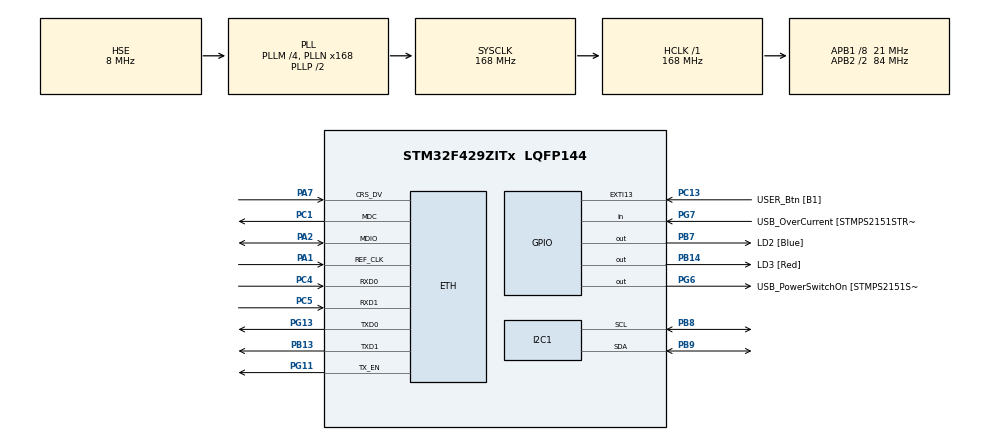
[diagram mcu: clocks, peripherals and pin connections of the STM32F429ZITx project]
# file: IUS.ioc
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ETH.MACAddr=00\:80\:E1\:E2\:13\:77
ETH.MediaInterface=ETH_MEDIA_INTERFACE_RMII
ETH.PhyAddress=0
LWIP.API_MSG_DEBUG=LWIP_DBG_ON
LWIP.AUTOIP_DEBUG=LWIP_DBG_ON
LWIP.DHCP_DEBUG=LWIP_DBG_ON
LWIP.DNS_DEBUG=LWIP_DBG_ON
LWIP.ICMP_DEBUG=LWIP_DBG_ON
LWIP.IGMP_DEBUG=LWIP_DBG_ON
LWIP.INET_DEBUG=LWIP_DBG_ON
LWIP.IP_DEBUG=LWIP_DBG_ON
LWIP.LWIP_DBG_TYPES_ON=LWIP_DBG_OFF
LWIP.LWIP_DNS=1
LWIP.LWIP_NETIF_LINK_CALLBACK=1
LWIP.LWIP_NETIF_LOOPBACK=1
LWIP.LWIP_NETIF_STATUS_CALLBACK=1
LWIP.LWIP_SNTP=1
LWIP.LWIP_STATS=1
LWIP.MEMP_NUM_PBUF=32
LWIP.MEMP_NUM_SYS_TIMEOUT=10
LWIP.MEMP_NUM_TCP_PCB_LISTEN=4
LWIP.MEMP_NUM_TCP_SEG=32
LWIP.MEM_SIZE=65536
LWIP.NETIF_DEBUG=LWIP_DBG_OFF
LWIP.PBUF_DEBUG=LWIP_DBG_OFF
LWIP.SOCKETS_DEBUG=LWIP_DBG_ON
LWIP.TCPIP_DEBUG=LWIP_DBG_OFF
LWIP.TCP_DEBUG=LWIP_DBG_OFF
LWIP.TCP_INPUT_DEBUG=LWIP_DBG_OFF
LWIP.TCP_OUTPUT_DEBUG=LWIP_DBG_OFF
LWIP.UDP_DEBUG=LWIP_DBG_OFF
LWIP.Version=v2.0.3_Cube
Mcu.Family=STM32F4
Mcu.Name=STM32F429ZITx
Mcu.Package=LQFP144
NVIC.PriorityGroup=NVIC_PRIORITYGROUP_4
NVIC.TIM2_IRQn=true\:0\:0\:false\:false\:true\:true
PA1.Mode=RMII
PA1.Signal=ETH_REF_CLK
PA13.GPIO_Label=TMS
PA13.Signal=SYS_JTMS-SWDIO
PA14.GPIO_Label=TCK
PA14.Signal=SYS_JTCK-SWCLK
PA2.Mode=RMII
PA2.Signal=ETH_MDIO
PA7.Mode=RMII
PA7.Signal=ETH_CRS_DV
PB13.Mode=RMII
PB13.Signal=ETH_TXD1
PB14.GPIO_Label=LD3 [Red]
PB14.Signal=GPIO_Output
PB7.GPIO_Label=LD2 [Blue]
PB7.Signal=GPIO_Output
PB8.Mode=I2C
PB8.Signal=I2C1_SCL
PB9.Mode=I2C
PB9.Signal=I2C1_SDA
PC1.Mode=RMII
PC1.Signal=ETH_MDC
PC13.GPIO_Label=USER_Btn [B1]
PC13.Signal=GPXTI13
PC14/OSC32_IN.Mode=LSE-External-Oscillator
PC14/OSC32_IN.Signal=RCC_OSC32_IN
PC15/OSC32_OUT.Mode=LSE-External-Oscillator
PC15/OSC32_OUT.Signal=RCC_OSC32_OUT
PC4.Mode=RMII
PC4.Signal=ETH_RXD0
PC5.Mode=RMII
PC5.Signal=ETH_RXD1
PG11.Mode=RMII
PG11.Signal=ETH_TX_EN
PG13.Mode=RMII
PG13.Signal=ETH_TXD0
PG6.GPIO_Label=USB_PowerSwitchOn [STMPS2151STR_EN]
PG6.Signal=GPIO_Output
PG7.GPIO_Label=USB_OverCurrent [STMPS2151STR_FAULT]
PG7.Signal=GPIO_Input
PH0/OSC_IN.GPIO_Label=MCO [STM32F103CBT6_PA8]
PH0/OSC_IN.Mode=HSE-External-Clock-Source
PH0/OSC_IN.Signal=RCC_OSC_IN
PH1/OSC_OUT.Mode=HSE-External-Clock-Source
PH1/OSC_OUT.Signal=RCC_OSC_OUT
ProjectManager.HeapSize=0x200
ProjectManager.StackSize=0x400
ProjectManager.TargetToolchain=EWARM V8
RCC.48MHZClocksFreq_Value=48000000
RCC.AHBFreq_Value=168000000
RCC.APB1CLKDivider=RCC_HCLK_DIV8
RCC.APB1Freq_Value=21000000
RCC.APB1TimFreq_Value=42000000
RCC.APB2CLKDivider=RCC_HCLK_DIV2
RCC.APB2Freq_Value=84000000
RCC.APB2TimFreq_Value=168000000
RCC.CortexFreq_Value=168000000
RCC.HCLKFreq_Value=168000000
RCC.HSE_VALUE=8000000
RCC.HSI_VALUE=16000000
RCC.PLLM=4
RCC.PLLMUL=RCC_PLL_MUL9
RCC.PLLN=168
RCC.PLLQ=7
RCC.PLLSourceVirtual=RCC_PLLSOURCE_HSE
RCC.PRESCALERUSB=RCC_USBCLKSOURCE_PLL_DIV1_5
RCC.SYSCLKFreq_VALUE=168000000
RCC.SYSCLKSource=RCC_SYSCLKSOURCE_PLLCLK
RCC.SYSCLKSourceVirtual=RCC_SYSCLKSOURCE_PLLCLK
RCC.USBFreq_Value=48000000
RCC.VCOOutputFreq_Value=336000000
TIM2.Period=300000
TIM2.Prescaler=41999
VP_LWIP_VS_Enabled.Mode=Enabled
VP_TIM2_VS_ClockSourceINT.Mode=Internal
board=NUCLEO-F429ZI

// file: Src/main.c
/**
  ******************************************************************************
  * @file           : main.c
  * @brief          : Main program body
  ******************************************************************************
  * This notice applies to any and all portions of this file
  * that are not between comment pairs USER CODE BEGIN and
  * USER CODE END. Other portions of this file, whether
  * inserted by the user or by software development tools
  * are owned by their respective copyright owners.
  *
  * Copyright (c) 2018 STMicroelectronics International N.V.
  * All rights reserved.
  *
  * Redistribution and use in source and binary forms, with or without
  * modification, are permitted, provided that the following conditions are met:
  *
  * 1. Redistribution of source code must retain the above copyright notice,
  *    this list of conditions and the following disclaimer.
  * 2. Redistributions in binary form must reproduce the above copyright notice,
  *    this list of conditions and the following disclaimer in the documentation
  *    and/or other materials provided with the distribution.
  * 3. Neither the name of STMicroelectronics nor the names of other
  *    contributors to this software may be used to endorse or promote products
  *    derived from this software without specific written permission.
  * 4. This software, including modifications and/or derivative works of this
  *    software, must execute solely and exclusively on microcontroller or
  *    microprocessor devices manufactured by or for STMicroelectronics.
  * 5. Redistribution and use of this software other than as permitted under
  *    this license is void and will automatically terminate your rights under
  *    this license.
  *
  * THIS SOFTWARE IS PROVIDED BY STMICROELECTRONICS AND CONTRIBUTORS "AS IS"
  * AND ANY EXPRESS, IMPLIED OR STATUTORY WARRANTIES, INCLUDING, BUT NOT
  * LIMITED TO, THE IMPLIED WARRANTIES OF MERCHANTABILITY, FITNESS FOR A
  * PARTICULAR PURPOSE AND NON-INFRINGEMENT OF THIRD PARTY INTELLECTUAL PROPERTY
  * RIGHTS ARE DISCLAIMED TO THE FULLEST EXTENT PERMITTED BY LAW. IN NO EVENT
  * SHALL STMICROELECTRONICS OR CONTRIBUTORS BE LIABLE FOR ANY DIRECT, INDIRECT,
  * INCIDENTAL, SPECIAL, EXEMPLARY, OR CONSEQUENTIAL DAMAGES (INCLUDING, BUT NOT
  * LIMITED TO, PROCUREMENT OF SUBSTITUTE GOODS OR SERVICES; LOSS OF USE, DATA,
  * OR PROFITS; OR BUSINESS INTERRUPTION) HOWEVER CAUSED AND ON ANY THEORY OF
  * LIABILITY, WHETHER IN CONTRACT, STRICT LIABILITY, OR TORT (INCLUDING
  * NEGLIGENCE OR OTHERWISE) ARISING IN ANY WAY OUT OF THE USE OF THIS SOFTWARE,
  * EVEN IF ADVISED OF THE POSSIBILITY OF SUCH DAMAGE.
  *
  ******************************************************************************
  */
#include "main.h"
#include "stm32f4xx_hal.h"
#include "lwip.h"

/* USER CODE BEGIN Includes */
#include "local_time.h"
#include "temperature.h"
#include "memory.h"
/* USER CODE END Includes */

I2C_HandleTypeDef hi2c1;

TIM_HandleTypeDef htim2;

/* USER CODE BEGIN PV */
extern struct netif gnetif;
/* Private variables ---------------------------------------------------------*/

/* USER CODE END PV */

void SystemClock_Config(void);
static void MX_GPIO_Init(void);
static void MX_I2C1_Init(void);
static void MX_TIM2_Init(void);

/* USER CODE BEGIN PFP */
/* Private function prototypes -----------------------------------------------*/
/* USER CODE END PFP */

int main(void)
{
  /* USER CODE BEGIN 1 */
  set_i2c_handler(&hi2c1);

  /* USER CODE END 1 */

  /* MCU Configuration----------------------------------------------------------*/

  /* Reset of all peripherals, Initializes the Flash interface and the Systick. */
  HAL_Init();

  /* Configure the system clock */
  SystemClock_Config();

  /* Initialize all configured peripherals */
  MX_GPIO_Init();
  MX_LWIP_Init();
  MX_I2C1_Init();
  MX_TIM2_Init();
  /* USER CODE BEGIN 2 */
  HAL_GPIO_TogglePin(GPIOB, LD3_Pin);
  configure_mode_and_oversampling();
  set_time_offset(180);
  HAL_TIM_Base_Start_IT(&htim2);
  /* USER CODE END 2 */

  /* Infinite loop */
  /* USER CODE BEGIN WHILE */
  while (1) {

    MX_LWIP_Process();
    update_records();
    HAL_Delay(100);
  /* USER CODE END WHILE */

  }

}

void SystemClock_Config(void)
{

  RCC_OscInitTypeDef RCC_OscInitStruct;
  RCC_ClkInitTypeDef RCC_ClkInitStruct;

    /**Configure the main internal regulator output voltage
    */
  __HAL_RCC_PWR_CLK_ENABLE();

  __HAL_PWR_VOLTAGESCALING_CONFIG(PWR_REGULATOR_VOLTAGE_SCALE1);

    /**Initializes the CPU, AHB and APB busses clocks
    */
  RCC_OscInitStruct.OscillatorType = RCC_OSCILLATORTYPE_HSE;
  RCC_OscInitStruct.HSEState = RCC_HSE_BYPASS;
  RCC_OscInitStruct.PLL.PLLState = RCC_PLL_ON;
  RCC_OscInitStruct.PLL.PLLSource = RCC_PLLSOURCE_HSE;
  RCC_OscInitStruct.PLL.PLLM = 4;
  RCC_OscInitStruct.PLL.PLLN = 168;
  RCC_OscInitStruct.PLL.PLLP = RCC_PLLP_DIV2;
  RCC_OscInitStruct.PLL.PLLQ = 7;
  if (HAL_RCC_OscConfig(&RCC_OscInitStruct) != HAL_OK)
  {
    _Error_Handler(__FILE__, __LINE__);
  }

    /**Initializes the CPU, AHB and APB busses clocks
    */
  RCC_ClkInitStruct.ClockType = RCC_CLOCKTYPE_HCLK|RCC_CLOCKTYPE_SYSCLK
                              |RCC_CLOCKTYPE_PCLK1|RCC_CLOCKTYPE_PCLK2;
  RCC_ClkInitStruct.SYSCLKSource = RCC_SYSCLKSOURCE_PLLCLK;
  RCC_ClkInitStruct.AHBCLKDivider = RCC_SYSCLK_DIV1;
  RCC_ClkInitStruct.APB1CLKDivider = RCC_HCLK_DIV8;
  RCC_ClkInitStruct.APB2CLKDivider = RCC_HCLK_DIV2;

  if (HAL_RCC_ClockConfig(&RCC_ClkInitStruct, FLASH_LATENCY_5) != HAL_OK)
  {
    _Error_Handler(__FILE__, __LINE__);
  }

    /**Configure the Systick interrupt time
    */
  HAL_SYSTICK_Config(HAL_RCC_GetHCLKFreq()/1000);

    /**Configure the Systick
    */
  HAL_SYSTICK_CLKSourceConfig(SYSTICK_CLKSOURCE_HCLK);

  /* SysTick_IRQn interrupt configuration */
  HAL_NVIC_SetPriority(SysTick_IRQn, 0, 0);
}

/* I2C1 init function */
static void MX_I2C1_Init(void)
{

  hi2c1.Instance = I2C1;
  hi2c1.Init.ClockSpeed = 100000;
  hi2c1.Init.DutyCycle = I2C_DUTYCYCLE_2;
  hi2c1.Init.OwnAddress1 = 0;
  hi2c1.Init.AddressingMode = I2C_ADDRESSINGMODE_7BIT;
  hi2c1.Init.DualAddressMode = I2C_DUALADDRESS_DISABLE;
  hi2c1.Init.OwnAddress2 = 0;
  hi2c1.Init.GeneralCallMode = I2C_GENERALCALL_DISABLE;
  hi2c1.Init.NoStretchMode = I2C_NOSTRETCH_DISABLE;
  if (HAL_I2C_Init(&hi2c1) != HAL_OK)
  {
    _Error_Handler(__FILE__, __LINE__);
  }

}

/* TIM2 init function */
static void MX_TIM2_Init(void)
{

  TIM_ClockConfigTypeDef sClockSourceConfig;
  TIM_MasterConfigTypeDef sMasterConfig;

  htim2.Instance = TIM2;
  htim2.Init.Prescaler = 41999;
  htim2.Init.CounterMode = TIM_COUNTERMODE_UP;
  htim2.Init.Period = 60000;
  htim2.Init.ClockDivision = TIM_CLOCKDIVISION_DIV1;
  if (HAL_TIM_Base_Init(&htim2) != HAL_OK)
  {
    _Error_Handler(__FILE__, __LINE__);
  }

  sClockSourceConfig.ClockSource = TIM_CLOCKSOURCE_INTERNAL;
  if (HAL_TIM_ConfigClockSource(&htim2, &sClockSourceConfig) != HAL_OK)
  {
    _Error_Handler(__FILE__, __LINE__);
  }

  sMasterConfig.MasterOutputTrigger = TIM_TRGO_RESET;
  sMasterConfig.MasterSlaveMode = TIM_MASTERSLAVEMODE_DISABLE;
  if (HAL_TIMEx_MasterConfigSynchronization(&htim2, &sMasterConfig) != HAL_OK)
  {
    _Error_Handler(__FILE__, __LINE__);
  }

}

/** Configure pins as
        * Analog
        * Input
        * Output
        * EVENT_OUT
        * EXTI
*/
static void MX_GPIO_Init(void)
{

  GPIO_InitTypeDef GPIO_InitStruct;

  /* GPIO Ports Clock Enable */
  __HAL_RCC_GPIOC_CLK_ENABLE();
  __HAL_RCC_GPIOH_CLK_ENABLE();
  __HAL_RCC_GPIOA_CLK_ENABLE();
  __HAL_RCC_GPIOB_CLK_ENABLE();
  __HAL_RCC_GPIOG_CLK_ENABLE();

  /*Configure GPIO pin Output Level */
  HAL_GPIO_WritePin(GPIOB, LD3_Pin|LD2_Pin, GPIO_PIN_RESET);

  /*Configure GPIO pin Output Level */
  HAL_GPIO_WritePin(USB_PowerSwitchOn_GPIO_Port, USB_PowerSwitchOn_Pin, GPIO_PIN_RESET);

  /*Configure GPIO pin : USER_Btn_Pin */
  GPIO_InitStruct.Pin = USER_Btn_Pin;
  GPIO_InitStruct.Mode = GPIO_MODE_IT_RISING;
  GPIO_InitStruct.Pull = GPIO_NOPULL;
  HAL_GPIO_Init(USER_Btn_GPIO_Port, &GPIO_InitStruct);

  /*Configure GPIO pins : LD3_Pin LD2_Pin */
  GPIO_InitStruct.Pin = LD3_Pin|LD2_Pin;
  GPIO_InitStruct.Mode = GPIO_MODE_OUTPUT_PP;
  GPIO_InitStruct.Pull = GPIO_NOPULL;
  GPIO_InitStruct.Speed = GPIO_SPEED_FREQ_LOW;
  HAL_GPIO_Init(GPIOB, &GPIO_InitStruct);

  /*Configure GPIO pin : USB_PowerSwitchOn_Pin */
  GPIO_InitStruct.Pin = USB_PowerSwitchOn_Pin;
  GPIO_InitStruct.Mode = GPIO_MODE_OUTPUT_PP;
  GPIO_InitStruct.Pull = GPIO_NOPULL;
  GPIO_InitStruct.Speed = GPIO_SPEED_FREQ_LOW;
  HAL_GPIO_Init(USB_PowerSwitchOn_GPIO_Port, &GPIO_InitStruct);

  /*Configure GPIO pin : USB_OverCurrent_Pin */
  GPIO_InitStruct.Pin = USB_OverCurrent_Pin;
  GPIO_InitStruct.Mode = GPIO_MODE_INPUT;
  GPIO_InitStruct.Pull = GPIO_NOPULL;
  HAL_GPIO_Init(USB_OverCurrent_GPIO_Port, &GPIO_InitStruct);

}

void _Error_Handler(char *file, int line)
{
  while(1)
  {
  }
}

/************************ (C) COPYRIGHT STMicroelectronics *****END OF FILE****/
